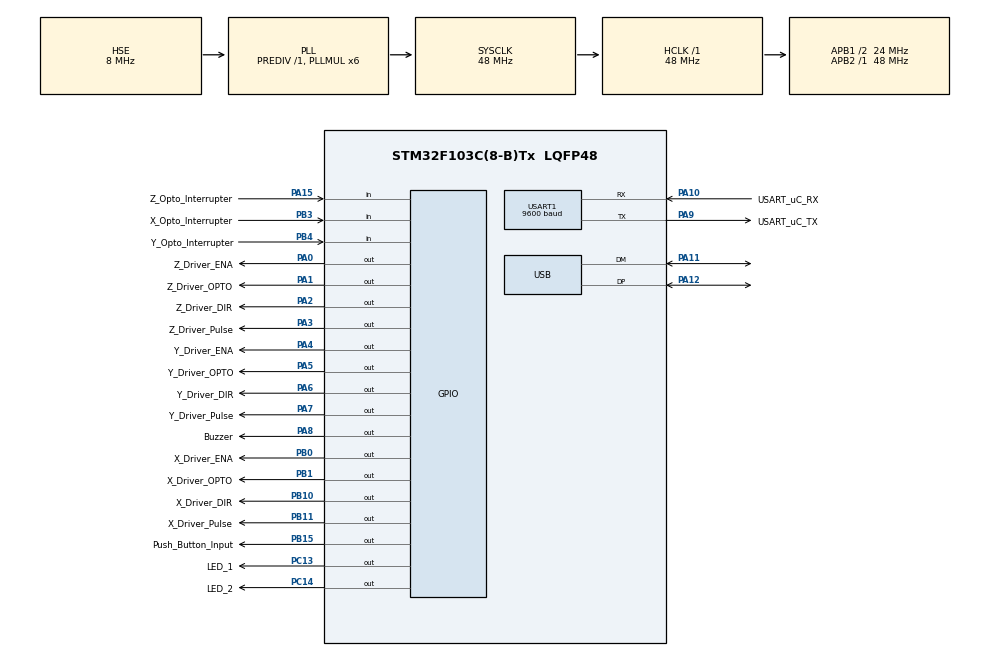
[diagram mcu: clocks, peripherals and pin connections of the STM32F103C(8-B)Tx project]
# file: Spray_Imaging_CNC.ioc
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Mcu.Family=STM32F1
Mcu.Name=STM32F103C(8-B)Tx
Mcu.Package=LQFP48
NVIC.PriorityGroup=NVIC_PRIORITYGROUP_4
NVIC.TIM1_UP_IRQn=true\:0\:0\:false\:false\:true\:true\:true\:true
NVIC.TIM2_IRQn=true\:0\:0\:false\:false\:true\:true\:true\:true
NVIC.TIM4_IRQn=true\:0\:0\:false\:false\:true\:true\:true\:true
NVIC.USART1_IRQn=true\:0\:0\:false\:false\:true\:true\:true\:true
NVIC.USB_HP_CAN1_TX_IRQn=true\:0\:0\:false\:false\:true\:true\:true\:true
NVIC.USB_LP_CAN1_RX0_IRQn=true\:0\:0\:false\:false\:true\:false\:true\:true
PA0-WKUP.GPIO_Label=Z_Driver_ENA
PA0-WKUP.Signal=GPIO_Output
PA1.GPIO_Label=Z_Driver_OPTO
PA1.Signal=GPIO_Output
PA10.GPIO_Label=USART_uC_RX
PA10.Mode=Asynchronous
PA10.Signal=USART1_RX
PA11.Mode=Device
PA11.Signal=USB_DM
PA12.Mode=Device
PA12.Signal=USB_DP
PA13.Mode=Serial_Wire
PA13.Signal=SYS_JTMS-SWDIO
PA14.Mode=Serial_Wire
PA14.Signal=SYS_JTCK-SWCLK
PA15.GPIO_Label=Z_Opto_Interrupter
PA15.Signal=GPIO_Input
PA2.GPIO_Label=Z_Driver_DIR
PA2.Signal=GPIO_Output
PA3.GPIO_Label=Z_Driver_Pulse
PA3.Signal=GPIO_Output
PA4.GPIO_Label=Y_Driver_ENA
PA4.Signal=GPIO_Output
PA5.GPIO_Label=Y_Driver_OPTO
PA5.Signal=GPIO_Output
PA6.GPIO_Label=Y_Driver_DIR
PA6.Signal=GPIO_Output
PA7.GPIO_Label=Y_Driver_Pulse
PA7.Signal=GPIO_Output
PA8.GPIO_Label=Buzzer
PA8.Signal=GPIO_Output
PA9.GPIO_Label=USART_uC_TX
PA9.Mode=Asynchronous
PA9.Signal=USART1_TX
PB0.GPIO_Label=X_Driver_ENA
PB0.Signal=GPIO_Output
PB1.GPIO_Label=X_Driver_OPTO
PB1.Signal=GPIO_Output
PB10.GPIO_Label=X_Driver_DIR
PB10.Signal=GPIO_Output
PB11.GPIO_Label=X_Driver_Pulse
PB11.Signal=GPIO_Output
PB15.GPIO_Label=Push_Button_Input
PB15.Signal=GPIO_Output
PB3.GPIO_Label=X_Opto_Interrupter
PB3.Signal=GPIO_Input
PB4.GPIO_Label=Y_Opto_Interrupter
PB4.Signal=GPIO_Input
PC13-TAMPER-RTC.GPIO_Label=LED_1
PC13-TAMPER-RTC.Signal=GPIO_Output
PC14-OSC32_IN.GPIO_Label=LED_2
PC14-OSC32_IN.Signal=GPIO_Output
PD0-OSC_IN.Mode=HSE-External-Oscillator
PD0-OSC_IN.Signal=RCC_OSC_IN
PD1-OSC_OUT.Mode=HSE-External-Oscillator
PD1-OSC_OUT.Signal=RCC_OSC_OUT
ProjectManager.HeapSize=0x300
ProjectManager.StackSize=0x500
ProjectManager.TargetToolchain=MDK-ARM V5.32
RCC.AHBFreq_Value=48000000
RCC.APB1CLKDivider=RCC_HCLK_DIV2
RCC.APB1Freq_Value=24000000
RCC.APB1TimFreq_Value=48000000
RCC.APB2Freq_Value=48000000
RCC.APB2TimFreq_Value=48000000
RCC.HCLKFreq_Value=48000000
RCC.PLLMUL=RCC_PLL_MUL6
RCC.PLLSourceVirtual=RCC_PLLSOURCE_HSE
RCC.SYSCLKFreq_VALUE=48000000
RCC.SYSCLKSource=RCC_SYSCLKSOURCE_PLLCLK
RCC.USBFreq_Value=48000000
TIM1.AutoReloadPreload=TIM_AUTORELOAD_PRELOAD_ENABLE
TIM1.Channel-Output\ Compare1\ No\ Output=TIM_CHANNEL_1
TIM1.Channel-Output\ Compare2\ No\ Output=TIM_CHANNEL_2
TIM1.Channel-Output\ Compare3\ No\ Output=TIM_CHANNEL_3
TIM1.Channel-Output\ Compare4\ No\ Output=TIM_CHANNEL_4
TIM1.Period=1000-1
TIM1.Prescaler=7200-1
TIM2.AutoReloadPreload=TIM_AUTORELOAD_PRELOAD_ENABLE
TIM2.Channel-Output\ Compare1\ No\ Output=TIM_CHANNEL_1
TIM2.Channel-Output\ Compare2\ No\ Output=TIM_CHANNEL_2
TIM2.Channel-Output\ Compare3\ No\ Output=TIM_CHANNEL_3
TIM2.Channel-Output\ Compare4\ No\ Output=TIM_CHANNEL_4
TIM2.Period=1000-1
TIM2.Prescaler=2250-1
TIM4.Period=50-1
TIM4.Prescaler=144-1
USART1.BaudRate=9600
USART1.VirtualMode=VM_ASYNC
USB_DEVICE.CLASS_NAME_FS=CDC
USB_DEVICE.VirtualMode=Cdc
USB_DEVICE.VirtualModeFS=Cdc_FS
VP_TIM1_VS_ClockSourceINT.Mode=Internal
VP_TIM1_VS_no_output1.Mode=Output Compare1 No Output
VP_TIM1_VS_no_output2.Mode=Output Compare2 No Output
VP_TIM1_VS_no_output3.Mode=Output Compare3 No Output
VP_TIM1_VS_no_output4.Mode=Output Compare4 No Output
VP_TIM2_VS_ClockSourceINT.Mode=Internal
VP_TIM2_VS_no_output1.Mode=Output Compare1 No Output
VP_TIM2_VS_no_output2.Mode=Output Compare2 No Output
VP_TIM2_VS_no_output3.Mode=Output Compare3 No Output
VP_TIM2_VS_no_output4.Mode=Output Compare4 No Output
VP_TIM4_VS_ClockSourceINT.Mode=Internal
VP_USB_DEVICE_VS_USB_DEVICE_CDC_FS.Mode=CDC_FS
board=custom

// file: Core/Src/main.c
/* USER CODE BEGIN Header */
/**
  ******************************************************************************
  * @file           : main.c
  * @brief          : Main program body
  ******************************************************************************
  * @attention
  *
  * Copyright (c) 2024 STMicroelectronics.
  * All rights reserved.
  *
  * This software is licensed under terms that can be found in the LICENSE file
  * in the root directory of this software component.
  * If no LICENSE file comes with this software, it is provided AS-IS.
  *
  ******************************************************************************
  */
/* USER CODE END Header */
#include "main.h"
#include "tim.h"
#include "usart.h"
#include "usb_device.h"
#include "gpio.h"

void SystemClock_Config(void);

int main(void)
{

  /* MCU Configuration--------------------------------------------------------*/

  /* Reset of all peripherals, Initializes the Flash interface and the Systick. */
  HAL_Init();

  /* Configure the system clock */
  SystemClock_Config();

  /* Initialize all configured peripherals */
  MX_GPIO_Init();
  MX_TIM1_Init();
  MX_TIM2_Init();
  MX_USART1_UART_Init();
  MX_TIM4_Init();
  MX_USB_DEVICE_Init();
  /* USER CODE BEGIN 2 */

  HAL_UART_Receive_IT(&huart1, rx_buff, 32);	//UART1 is used for PC Communcation
	HAL_TIM_Base_Start_IT(&htim2);
	HAL_TIM_Base_Start_IT(&htim4);

	Initialize_Axis_Parameters();
	Activate_Drivers();
  //Read_Home_Position_From_Flash_Memory();

	Alarm(SHORT_BEEP_X2, 1 , 32, 1);

  /* USER CODE END 2 */

  /* Infinite loop */
  while (1)
  {

  }
}

void SystemClock_Config(void)
{
  RCC_OscInitTypeDef RCC_OscInitStruct = {0};
  RCC_ClkInitTypeDef RCC_ClkInitStruct = {0};
  RCC_PeriphCLKInitTypeDef PeriphClkInit = {0};

  /** Initializes the RCC Oscillators according to the specified parameters
  * in the RCC_OscInitTypeDef structure.
  */
  RCC_OscInitStruct.OscillatorType = RCC_OSCILLATORTYPE_HSE;
  RCC_OscInitStruct.HSEState = RCC_HSE_ON;
  RCC_OscInitStruct.HSEPredivValue = RCC_HSE_PREDIV_DIV1;
  RCC_OscInitStruct.HSIState = RCC_HSI_ON;
  RCC_OscInitStruct.PLL.PLLState = RCC_PLL_ON;
  RCC_OscInitStruct.PLL.PLLSource = RCC_PLLSOURCE_HSE;
  RCC_OscInitStruct.PLL.PLLMUL = RCC_PLL_MUL6;
  if (HAL_RCC_OscConfig(&RCC_OscInitStruct) != HAL_OK)
  {
    Error_Handler();
  }

  /** Initializes the CPU, AHB and APB buses clocks
  */
  RCC_ClkInitStruct.ClockType = RCC_CLOCKTYPE_HCLK|RCC_CLOCKTYPE_SYSCLK
                              |RCC_CLOCKTYPE_PCLK1|RCC_CLOCKTYPE_PCLK2;
  RCC_ClkInitStruct.SYSCLKSource = RCC_SYSCLKSOURCE_PLLCLK;
  RCC_ClkInitStruct.AHBCLKDivider = RCC_SYSCLK_DIV1;
  RCC_ClkInitStruct.APB1CLKDivider = RCC_HCLK_DIV2;
  RCC_ClkInitStruct.APB2CLKDivider = RCC_HCLK_DIV1;

  if (HAL_RCC_ClockConfig(&RCC_ClkInitStruct, FLASH_LATENCY_1) != HAL_OK)
  {
    Error_Handler();
  }
  PeriphClkInit.PeriphClockSelection = RCC_PERIPHCLK_USB;
  PeriphClkInit.UsbClockSelection = RCC_USBCLKSOURCE_PLL;
  if (HAL_RCCEx_PeriphCLKConfig(&PeriphClkInit) != HAL_OK)
  {
    Error_Handler();
  }
}

void Error_Handler(void)
{
  __disable_irq();
  while (1)
  {
  }
}
